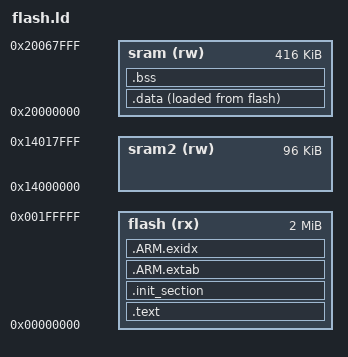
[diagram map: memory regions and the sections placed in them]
/****************************************************************************
 * boards/arm/mcx-nxxx/frdm-mcxn947/scripts/flash.ld
 *
 * SPDX-License-Identifier: Apache-2.0
 *
 * Licensed to the Apache Software Foundation (ASF) under one or more
 * contributor license agreements.  See the NOTICE file distributed with
 * this work for additional information regarding copyright ownership.  The
 * ASF licenses this file to you under the Apache License, Version 2.0 (the
 * "License"); you may not use this file except in compliance with the
 * License.  You may obtain a copy of the License at
 *
 *   http://www.apache.org/licenses/LICENSE-2.0
 *
 * Unless required by applicable law or agreed to in writing, software
 * distributed under the License is distributed on an "AS IS" BASIS, WITHOUT
 * WARRANTIES OR CONDITIONS OF ANY KIND, either express or implied.  See the
 * License for the specific language governing permissions and limitations
 * under the License.
 *
 *
 ****************************************************************************/

/*
 * MCXN947 has 2 MB of FLASH at 0x0000:0000 and 512 KB of on-chip SRAM,
 * but the SRAM is NOT one contiguous block: only 416 KB (RAMA..RAMH) sit
 * at 0x2000:0000; the remaining 96 KB is SRAMX over at 0x1400:0000 and is
 * added as a second heap region via CONFIG_MM_REGIONS=2.  Keep the linker
 * region at 416 KB (matches CONFIG_RAM_SIZE=425984) so an oversized
 * .data/.bss fails at link time instead of landing in nonexistent memory
 * and hardfaulting at boot.
 *    1) main SRAM (ECC capable) at 0x2000:0000, 416 KB
 *    2) SRAMX at 0x1400:0000, 96 KB (second heap region)
 */

MEMORY
{
  flash (rx) : ORIGIN = 0x00000000, LENGTH = 0x00200000 /* 2 MB */
  sram  (rw) : ORIGIN = 0x20000000, LENGTH = 416K /* main SRAM */
  sram2 (rw) : ORIGIN = 0x14000000, LENGTH = 96K  /* SRAMX */
}

OUTPUT_ARCH(arm)
EXTERN(_vectors)
ENTRY(__start)

SECTIONS
{
    .text :
    {
        _stext = ABSOLUTE(.);
        *(.vectors)
        *(.text .text.*)
        *(.fixup)
        *(.gnu.warning)
        *(.rodata .rodata.*)
        *(.gnu.linkonce.t.*)
        *(.glue_7)
        *(.glue_7t)
        *(.got)
        *(.gcc_except_table)
        *(.gnu.linkonce.r.*)
        _etext = ABSOLUTE(.);
    } > flash

    .init_section :
    {
        _sinit = ABSOLUTE(.);
        KEEP(*(SORT_BY_INIT_PRIORITY(.init_array.*) SORT_BY_INIT_PRIORITY(.ctors.*)))
        KEEP(*(.init_array .ctors))
        _einit = ABSOLUTE(.);
    } > flash

    .ARM.extab :
    {
        *(.ARM.extab*)
    } > flash

    __exidx_start = ABSOLUTE(.);
    .ARM.exidx :
    {
        *(.ARM.exidx*)
    } > flash
    __exidx_end = ABSOLUTE(.);

    _eronly = ABSOLUTE(.);

    .data :
    {
        _sdata = ABSOLUTE(.);
        *(.data .data.*)
        *(.gnu.linkonce.d.*)
        CONSTRUCTORS
        . = ALIGN(4);
        _edata = ABSOLUTE(.);
    } > sram AT > flash

    .bss :
    {
        _sbss = ABSOLUTE(.);
        *(.bss .bss.*)
        *(.gnu.linkonce.b.*)
        *(COMMON)
        . = ALIGN(4);
        _ebss = ABSOLUTE(.);
    } > sram

    /* Stabs debugging sections. */
    .stab 0 : { *(.stab) }
    .stabstr 0 : { *(.stabstr) }
    .stab.excl 0 : { *(.stab.excl) }
    .stab.exclstr 0 : { *(.stab.exclstr) }
    .stab.index 0 : { *(.stab.index) }
    .stab.indexstr 0 : { *(.stab.indexstr) }
    .comment 0 : { *(.comment) }
    .debug_abbrev 0 : { *(.debug_abbrev) }
    .debug_info 0 : { *(.debug_info) }
    .debug_line 0 : { *(.debug_line) }
    .debug_pubnames 0 : { *(.debug_pubnames) }
    .debug_aranges 0 : { *(.debug_aranges) }
}
